# USB_TLL_HS_CONFIG register map
Vendor: Texas Instruments
Peripheral module from a debugger description file (folder omap5430_ES2_PUBLIC).
Registers are 32-bit, read-write, reset 0x0 unless marked. A register's access mark holds for its fields unless they carry their own. Offsets are as the file gives them; lines under a group give offsets from that group; [hi:lo] are bit positions; {n}, {i} and the like mark numbered series; 'fields as' and 'values as' point back to an identical list; <NAME> marks a mode.

## USB_TLL_HS_CONFIG
0x00 USBTLL_REVISION ro reset not defined — OCP standard revision number, BCD encoded
  [31:0] REVISION — Revision number
0x04 USBTLL_HWINFO ro reset 0x7 — Information on hardware configuration of host
  [7:0] SAR_CNTX_SIZE — Save-and-Restore context size, in 32-bit words, i.e. number of 32-bit registers with significant context information, mapped from offset 0x400 upward.
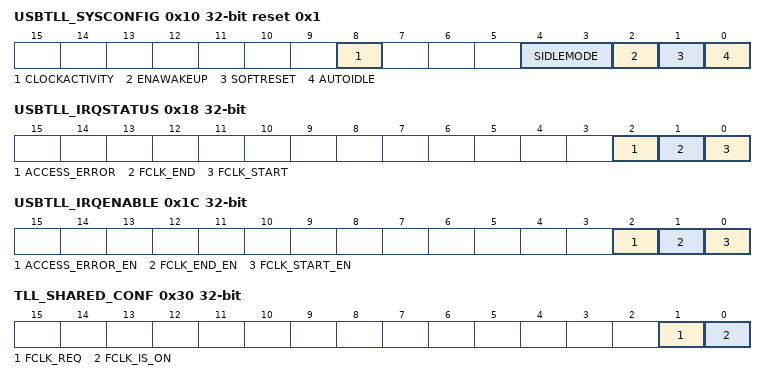
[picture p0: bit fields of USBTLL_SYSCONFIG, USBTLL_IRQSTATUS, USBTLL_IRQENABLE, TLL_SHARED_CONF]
0x10 USBTLL_SYSCONFIG access per field reset 0x1 — OCP standard system configuration register
  [8] CLOCKACTIVITY rw — Enable autogating of OCP-derived internal clocks while module is idle.
    0=OFF_0 (OCP-derived internal clocks OFF during idle); 1=ON_1 (OCP-derived internal clocks ON during idle)
  [4:3] SIDLEMODE rw — Slave interface power management control. Idle Req/ack control
    0=Force-idle mode. Sidleack[1] asserted after Sidlereq assertion; 1=No-idle mode. Sidleack[1] never asserted.; 2=Smart-idle mode. Sidleack[1] asserted after Sidlereq assertion when no more activity on the OCP.
  [2] ENAWAKEUP rw — Asynchronous wake-up generation control (Swakeup)
    0=disabled (Wake-up generation disabled); 1=enabled (Wake-up generation enabled)
  [1] SOFTRESET wo — Module software reset
    0=no_action (No effect); 1=do_reset (Starts softreset sequence.)
  [0] AUTOIDLE rw — Internal autogating control
    0=disabled (Clock always running); 1=enabled (When no activity on OCP, clock is cut off.)
0x14 USBTLL_SYSSTATUS ro — OCP standard system status register
  [0] RESETDONE — Indicates when the module has entirely come out of reset
    0=ongoing (Reset is ongoing); 1=done (Reset is done)
0x18 USBTLL_IRQSTATUS access per field — OCP standard IRQ status vector. Write 1 to clear a bit.
  [all] fields
    0=Pending (No event pending); 1=Pending (Event pending)
  [2] ACCESS_ERROR rw — Access error to ULPI register over OCP: USB clock must run for that type of access to succeed.
  [1] FCLK_END rw — Functional clock is no longer requested for USB clocking
  [0] FCLK_START rw — Functional clock is requested for USB clocking
0x1C USBTLL_IRQENABLE access per field — OCP standard IRQ enable vector
  [all] fields
    0=Masked (IRQ event is masked); 1=Enabled (IRQ event is enabled)
  [2] ACCESS_ERROR_EN rw — Enable IRQ generation upon access error to ULPI register over L3 interconnect
  [1] FCLK_END_EN rw — IRQ event mask for FCLK_END interrupt (seeUSBTLL_IRQSTATUS[1])
  [0] FCLK_START_EN rw — IRQ event mask for FCLK_START interrupt (seeUSBTLL_IRQSTATUS[0])
0x30 TLL_SHARED_CONF access per field — Common control register for all TLL channels
  [1] FCLK_REQ ro — Functional clock request, ORed from all channels depending on their respective USB bus state. Combined with the Fclk_is_on status to generate fclk_start/end IRQs.
    0=NoRequest (Func clock input is not requested by TLL); 1=Request (Func clock input is requested by TLL)
  [0] FCLK_IS_ON rw — Status of the functional clock input, provided by the system to the TLL module. The TLL module will only use that clock if the current status indicated that it is ready. Combined with the Fclk_request to generate fclk_start/end IRQs.
    0=not_ready (Functional clock input is not guaranteed ON (can actually be ON, OFF, or unstable)); 1=ready (Functional clock input is guaranteed ON and stable)
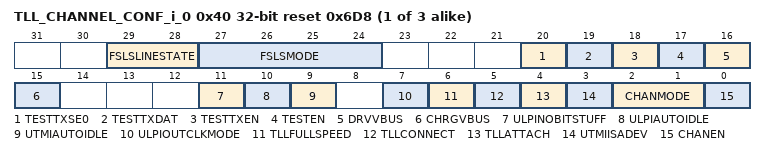
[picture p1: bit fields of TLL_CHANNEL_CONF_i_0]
{0x40+4i} TLL_CHANNEL_CONF_i_{i} access not given reset 0x6D8 (i=0..2) — Control and Status register for channel i.
  [29:28] FSLSLINESTATE ro — Line state for Full/low speed serial modes Bit 1 = D–/ Bit0 = D+
    0=Single-ended_0; 1=Full-Speed_J_=_differential_1; 2=Full-Speed_K_=_differential_0; 3=Single-ended_1_(illegal_in_USB)
  [27:24] FSLSMODE rw — Multiple-mode serial interface's mode select. Only when main channel mode is serial. No effect in other main modes.
    0=PHY_TX_0 (6-pin unidirectional PHY i/f mode. TX encoding is Dat/Se0 (default).); 1=PHY_TX_1 (6-pin unidirectional PHY i/f mode. TX encoding is Dp/Dm.); 2=3-pin_bidirectional_PHY_i/f_mode; 3=4-pin_bidirectional_PHY_i/f_mode; 4=TLL_TX_4 (6-pin unidirectional TLL mode. TX encoding is Dat/Se0.); 5=TLL_TX_5 (6-pin unidirectional TLL mode. TX encoding is Dp/Dm.); 6=3-pin_bidirectional_TLL_mode; 7=4-pin_bidirectional_TLL_mode; 10=TLL_10 (2-pin bidirectional TLL mode. Encoding is Dat/Se0.); 11=TLL_11 (2-pin bidirectional TLL mode. Encoding is Dp/Dm.)
  [20] TESTTXSE0 rw — Force-Se0 transmit override value for serial mode test Don't care if TestEn = 0 (functional mode) or = TestTxen = 1 (TX = hiz)
    0=TX_0 (drive differential value on TX according to TestTxDat); 1=drive_SE0_on_TX
  [19] TESTTXDAT rw — Differential data transmit override value for serial mode test Don't care if TestEn = 0 (functional mode) or = TestTxen = 1 (TX = hiz) or TestSe0 = 1 (TX = se0)
    0=Drive_full-speed_K_=_differential_0; 1=Drive_full-speed_J_=_differential_1
  [18] TESTTXEN rw — Differential data transmit override value for serial mode test Don't care if TestEn = 0 (functional mode)
    0=Drive_Tx_according_to_TestTxDat/Se0; 1=Drive Tx Hiz (no drive: pullups determine line state)
  [17] TESTEN rw — Enable manual test override for serial mode TX path (from local controller UTMI port)
    0=No override. Tx is from local link controller; 1=Override_enabled
  [16] DRVVBUS rw — VBUS-drive for ChanMode = serial * In TLL config, write 1 to emulate serial-side VBUS drive * In PHY config, write 1 to report 'VBUS valid' status (of actual VBUS) to UTMI controller
    0=VBUS_not_driven; 1=VBUS_driven_to_5_V
  [15] CHRGVBUS rw — VBUS-drive for ChanMode = serial * In TLL config, write 1 to emulate serial-side VBUS charge/pullup (OTG) * In PHY config, write 1 to reports 'session valid' status (of actual VBUS) to UTMI controller
    0=VBUS_not_charged,_session_not_valid; 1=VBUS_charged,_session_valid
  [11] ULPINOBITSTUFF rw — Disable bitstuff emulation in ULPI TLL for ULPI ChanMode
    0=USB_0 (Bitstuff enabled, following USB standard); 1=No bitstuff or associated delays (nonstandard)
  [10] ULPIAUTOIDLE rw — For ChanMode = ULPI TLL only. Allow the ULPI output clock to be stopped when ULPI goes into asynchronous mode (low-power, 3-pin serial, 6-pin serial). No effect in ULPI input clock mode.
    0=ULPI_output_clock_always-on; 1=ULPI_ULPI_1 (ULPI output clock stops during asynchronous ULPI modes)
  [9] UTMIAUTOIDLE rw — For ChanMode = ULPI TLL only. Allow the UTMI clock (output) to be stopped when UTMII goes to suspended mode (suspendm = 0)
    0=UTMI_clock_output_always_on; 1=UTMI_clock_output_gated_upon_suspend
  [7] ULPIOUTCLKMODE — ULPI clocking mode select for ULPI TLL ChanMode. Hardcoded, for legacy only. (access R Rreturns1s)
    1=ULPI_PHY_TLL,_ULPI_1 (ULPI clock provided by PHY side (i.e. TLL, from functional clock). ULPI clock is output)
  [6] TLLFULLSPEED rw — Sets PHY speed emulation in TLL (full/slow), which determines the line to pull up upon connect. The two connect source controls are: input m(N)_tllpuen, register field TllConnect.
    0=Connect_is_Low-speed:_D–_pullup; 1=Connect_is_Full-Speed:_D+_pullup
  [5] TLLCONNECT rw — Emulation of Full/Low-Speed connect (that is, D+ resp D– pullup) for serial TLL modes. Speed is determined by field TllSpeed.
    0=Unconnected; 1=Connected
  [4] TLLATTACH rw — Emulates cable attach/detach for all serial TLL modes: * ChanMode = serial, in TLL mode (FsLsMode) * ChanMode = ULPI, in serial mode (6pin/3pin TLL)
    0=Cable_detach_emulated_on_serial_TLL; 1=Cable_attach_emulated_on_serial_TLL
  [3] UTMIISADEV rw — Select the cable end 'seen' by UTMI side of TLL, i.e. the emulated USB cable's orientation. The host must always be on A-side, peripheral on B-side. Reset value depends on generic DEFUTMIISHOST.
    0=UTMI_ULPI_0 (UTMI side is peripheral, ULPI side is host); 1=UTMI_ULPI_1 (UTMI side is host, ULPI side is peripheral)
  [2:1] CHANMODE rw — Main channel mode selection
    0=TLL_(HS_ULPI_0 (UTMI-to-ULPI TLL mode (HS capable): to ULPI controller); 1=(FS/LS)_(TLL)_PHY_1 (UTMI-to-serial (FS/LS) mode: to serial controller (TLL) or serial PHY); 2=Transparent_UTMI_mode:_to_UTMI_PHY; 3=No_mode_selected
  [0] CHANEN rw — Active-high channel enable. A disabled channel is unclocked and kept under reset.
    0=Channel_i_disabled; 1=Channel_i_enabled
{0x400+4i} USBTLL_SAR_CNTX_j_{i} (i=0..6) — Save and Restore context array. Array size is indicated in. When in SAR mode, read to save and write to restore. Do not access when not in SAR mode.
  [31:0] CNTX — Context bits
